# LIS331EB register map
Vendor: STMicroelectronics; Series: LIS331EB; File version: 1.0
ARM 32-bit Cortex-M0 Microcontroller based device, CPU clock up to 80MHz.
CPU: CM0 r0p0, little endian, no MPU, no FPU, 5 interrupt priority bits
Registers are 32-bit, read-write, reset 0x0 unless marked. A register's access mark holds for its fields unless they carry their own. Offsets are from the block's base; lines under a group give offsets from that group; [hi:lo] are bit positions; {n}, {i} and the like mark numbered series; 'fields as' and 'values as' point back to an identical list; <NAME> marks a mode.

## Memory map
0xA0000000 GPIO size 0x1000 — GPIO Controller
0xA1000000 FLASH size 0x1000 — Flash Controller
0xA2000000 UART size 0x1000 — PrimeCell UART (PL011)
0xA3000000 SPI1 size 0x1000 — PrimeCell Synchronous Serial Port (PL022)
0xA4000000 I2CM size 0x1000 — I2C Master
0xA5000000 I2CS size 0x1000
0xA6000000 TIMER0 size 0x1000
0xA6400000 DUALTIMER0 size 0x1000
0xA6800000 DUALTIMER4 size 0x1000
0xA7000000 TIMER1 size 0x1000
0xA7400000 DUALTIMER1 size 0x1000
0xA7800000 DUALTIMER5 size 0x1000
0xA8000000 TIMER2 size 0x1000
0xA8400000 DUALTIMER2 size 0x1000
0xA8800000 DUALTIMER6 size 0x1000
0xA9000000 TIMER3 size 0x1000
0xA9400000 DUALTIMER3 size 0x1000
0xA9800000 DUALTIMER7 size 0x1000
0xAA000000 WATCHDOG size 0x1000
0xAB000000 CRMU size 0x1000 — Clock and Reset Management Unit

## Interrupts
0 GPIO
1 NVM (FLASH)
2 Timer0 (TIMER0)
3 Timer1 (TIMER1)
4 Timer2 (TIMER2)
5 Timer3 (TIMER3)
6 UART
7 SPI1
8 I2CM
9 I2CS
11 Watchdog (WATCHDOG)
{2n+12} DualTimer{n}A (DUALTIMER{n}) (n=0..7)
{2n+13} DualTimer{n}B (DUALTIMER{n}) (n=0..7)

## GPIO — GPIO Controller
Base 0xA0000000
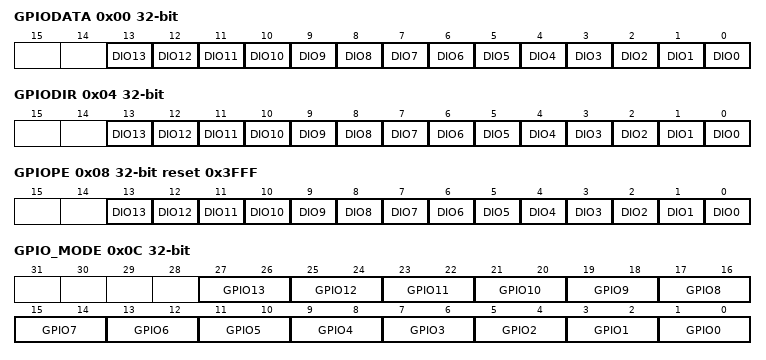
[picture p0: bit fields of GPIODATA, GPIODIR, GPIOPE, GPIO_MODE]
0x00 GPIODATA — Data register
  [n] DIO{n} (n=0..13) — DIO{n} output value
0x04 GPIODIR — Data direction register
  [all] fields
    0=Input; 1=Output
  [n] DIO{n} (n=0..13) — DIO{n} output enable
0x08 GPIOPE reset 0x3FFF — Pull enable. Note DIO9 and DIO12 are pull-up while all others are pull down
  [13] DIO13 — DIO13 pull down enable
    0=No_pull_down; 1=Pull_down
  [12] DIO12 — DIO12 pull-up enable
    0=No_pull_up; 1=Pull_up
  [11] DIO11 — DIO11 pull down enable
    0=No_pull_down; 1=Pull_down
  [10] DIO10 — DIO10 pull down enable
    0=No_pull_down; 1=Pull_down
  [9] DIO9 — DIO9 pull-up
    0=No_pull_up; 1=Pull_up
  [n] DIO{n} (n=0..8) — DIO{n} pull down enable
    0=No_pull_down; 1=Pull_down
0x0C GPIO_MODE
  [27:26] GPIO13 — GPIO13 mode
    1=Input_DIO10; 2=GPIO
  [25:24] GPIO12 — GPIO12 mode
    1=Input_DIO9; 2=GPIO
  [23:22] GPIO11 — GPIO11 mode
    1=Input_DIO6; 2=GPIO
  [21:20] GPIO10 — GPIO10 mode
    1=SPI_MOSI; 2=GPIO
  [19:18] GPIO9 — GPIO9 mode
    1=SPI_CS; 2=GPIO
  [17:16] GPIO8 — GPIO8 mode
    0=I2C_MDA; 1=SPI_MISO; 2=GPIO
  [15:14] GPIO7 — GPIO7 mode
    0=I2C_MCL; 1=SPI_CLK; 2=GPIO
  [13:12] GPIO6 — GPIO6 mode
    0=CLK80M; 1=CLK32K; 2=GPIO
  [11:10] GPIO5 — GPIO5 mode
    0=TDI; 2=GPIO
  [9:8] GPIO4 — GPIO4 mode
    0=TDO; 2=GPIO
  [7:6] GPIO3 — GPIO3 mode
    0=I2C_SDA; 1=UART_RXD; 2=GPIO
  [5:4] GPIO2 — GPIO2 mode
    0=I2C_SCL; 1=UART_TXD; 2=GPIO
  [3:2] GPIO1 — GPIO1 mode
    0=SW_TCK; 1=UART_RTS; 2=GPIO
  [1:0] GPIO0 — GPIO0 mode
    0=SW_TDIO; 1=UART_CTS; 2=GPIO
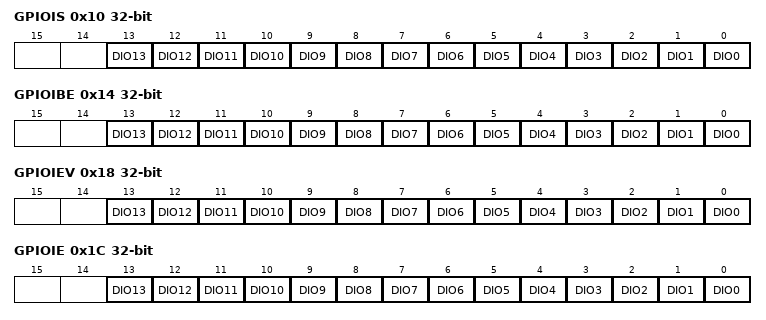
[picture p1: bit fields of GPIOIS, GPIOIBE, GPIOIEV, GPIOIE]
0x10 GPIOIS — Interrupt sense register
  [all] fields
    0=Edge_detection; 1=Level_detection
  [n] DIO{n} (n=0..13) — DIO{n} sense
0x14 GPIOIBE — Interrupt both-edges register
  [all] fields
    0=Single_edge; 1=Both_edges
  [n] DIO{n} (n=0..13) — DIO{n} both-edges
0x18 GPIOIEV — Interrupt event register
  [all] fields
    0=Falling_edge_Low_level; 1=Rising_edge_High_level
  [n] DIO{n} (n=0..13) — DIO{n} event
0x1C GPIOIE — Interrupt mask register
  [all] fields
    0=Interrupt_masked; 1=Interrupt_not_masked
  [n] DIO{n} (n=0..13) — DIO{n} interrupt mask
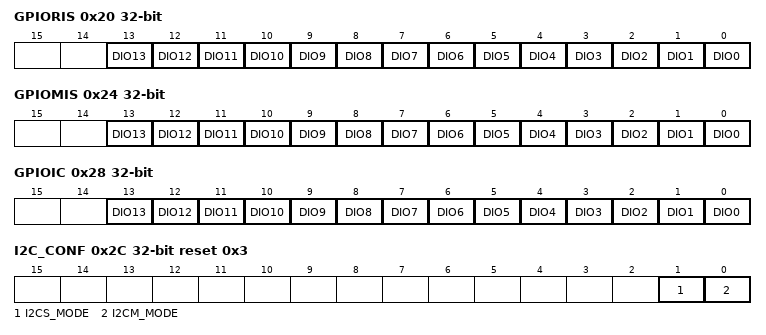
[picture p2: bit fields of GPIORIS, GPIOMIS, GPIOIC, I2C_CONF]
0x20 GPIORIS ro — Raw interrupt status register
  [all] fields
    0=Not_pending; 1=Pending
  [n] DIO{n} (n=0..13) — DIO{n} raw interrupt status
0x24 GPIOMIS ro — Masked interrupt status register
  [all] fields
    0=Not_pending; 1=Pending
  [n] DIO{n} (n=0..13) — DIO{n} masked interrupt status
0x28 GPIOIC wo write-1-clears — Interrupt clear register
  [n] DIO{n} ro (n=1..13) — DIO{n} interrupt clear
  [0] DIO0 — DIO0 interrupt clear
0x2C I2C_CONF reset 0x3 — Bit 0 set to 1 enable the I2C mode on the pads master (Data and clock). Bit 1 set to 1 enables the I2C mode on the pads slave (Data only)
  [1] I2CS_MODE — Enables I2C mode on the pads slave (Data only)
  [0] I2CM_MODE — Enables I2C mode on the pads master (Data and clock)

## Licence text in the file
Licenza
